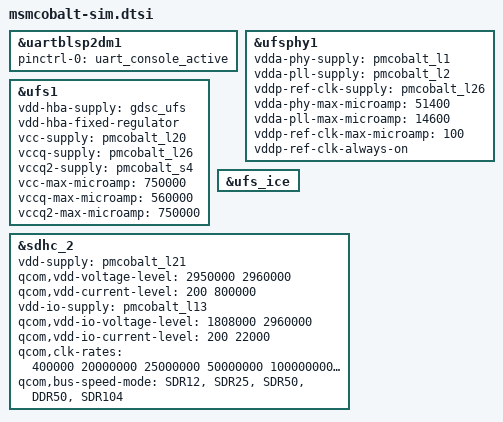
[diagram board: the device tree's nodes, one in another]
/* Copyright (c) 2015-2016, The Linux Foundation. All rights reserved.
 *
 * This program is free software; you can redistribute it and/or modify
 * it under the terms of the GNU General Public License version 2 and
 * only version 2 as published by the Free Software Foundation.
 *
 * This program is distributed in the hope that it will be useful,
 * but WITHOUT ANY WARRANTY; without even the implied warranty of
 * MERCHANTABILITY or FITNESS FOR A PARTICULAR PURPOSE.  See the
 * GNU General Public License for more details.
 */

#include "msmcobalt-pinctrl.dtsi"

&uartblsp2dm1 {
	status = "ok";
	pinctrl-names = "default";
	pinctrl-0 = <&uart_console_active>;
};

&ufsphy1 {
	vdda-phy-supply = <&pmcobalt_l1>;
	vdda-pll-supply = <&pmcobalt_l2>;
	vddp-ref-clk-supply = <&pmcobalt_l26>;
	vdda-phy-max-microamp = <51400>;
	vdda-pll-max-microamp = <14600>;
	vddp-ref-clk-max-microamp = <100>;
	vddp-ref-clk-always-on;
	status = "ok";
};

&ufs1 {
	vdd-hba-supply = <&gdsc_ufs>;
	vdd-hba-fixed-regulator;
	vcc-supply = <&pmcobalt_l20>;
	vccq-supply = <&pmcobalt_l26>;
	vccq2-supply = <&pmcobalt_s4>;
	vcc-max-microamp = <750000>;
	vccq-max-microamp = <560000>;
	vccq2-max-microamp = <750000>;
	status = "ok";
};

&ufs_ice {
	status = "ok";
};

&sdhc_2 {
	vdd-supply = <&pmcobalt_l21>;
	qcom,vdd-voltage-level = <2950000 2960000>;
	qcom,vdd-current-level = <200 800000>;

	vdd-io-supply = <&pmcobalt_l13>;
	qcom,vdd-io-voltage-level = <1808000 2960000>;
	qcom,vdd-io-current-level = <200 22000>;

	qcom,clk-rates = <400000 20000000 25000000
				50000000 100000000 200000000>;
	qcom,bus-speed-mode = "SDR12", "SDR25", "SDR50", "DDR50", "SDR104";

	status = "ok";
};
